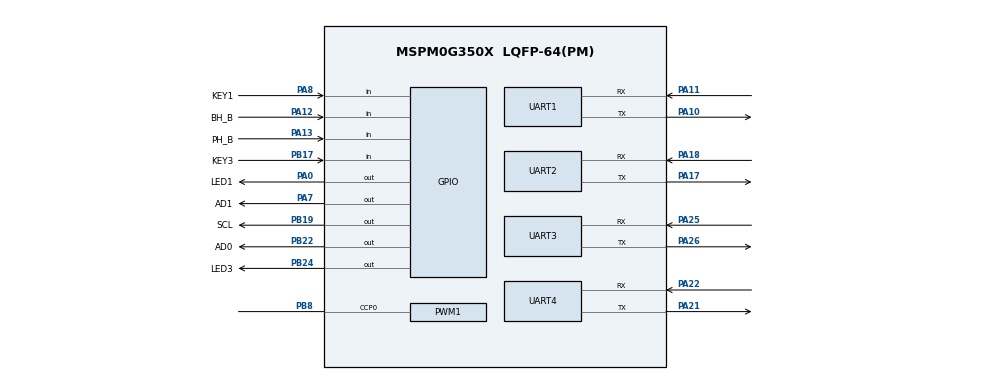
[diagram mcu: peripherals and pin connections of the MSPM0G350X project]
/**
 * @cliArgs --device "MSPM0G350X" --part "Default" --package "LQFP-64(PM)" --product "mspm0_sdk@2.09.00.00"
 * @versions {"tool":"1.26.0+4407"}
 */

/**
 * Import the modules used in this configuration.
 */
const ADC12   = scripting.addModule("/ti/driverlib/ADC12", {}, false);
const ADC121  = ADC12.addInstance();
const GPIO    = scripting.addModule("/ti/driverlib/GPIO", {}, false);
const GPIO1   = GPIO.addInstance();
const GPIO2   = GPIO.addInstance();
const GPIO3   = GPIO.addInstance();
const GPIO4   = GPIO.addInstance();
const GPIO5   = GPIO.addInstance();
const GPIO6   = GPIO.addInstance();
const GPIO7   = GPIO.addInstance();
const GPIO8   = GPIO.addInstance();
const PWM     = scripting.addModule("/ti/driverlib/PWM", {}, false);
const PWM1    = PWM.addInstance();
const PWM2    = PWM.addInstance();
const SYSCTL  = scripting.addModule("/ti/driverlib/SYSCTL");
const SYSTICK = scripting.addModule("/ti/driverlib/SYSTICK");
const TIMER   = scripting.addModule("/ti/driverlib/TIMER", {}, false);
const TIMER1  = TIMER.addInstance();
const UART    = scripting.addModule("/ti/driverlib/UART", {}, false);
const UART1   = UART.addInstance();
const UART2   = UART.addInstance();
const UART3   = UART.addInstance();
const UART4   = UART.addInstance();

/**
 * Write custom configuration values to the imported modules.
 */
ADC121.$name                             = "ADC12_sensor";
ADC121.sampleTime1                       = "0. ms";
ADC121.sampleTime0                       = "0.01 ms";
ADC121.peripheral.$assign                = "ADC0";
ADC121.peripheral.adcPin0.$assign        = "PA27";
ADC121.adcPin0Config.$name               = "ti_driverlib_gpio_GPIOPinGeneric0";
ADC121.adcPin0Config.hideOutputInversion = scripting.forceWrite(false);

const Board = scripting.addModule("/ti/driverlib/Board", {}, false);

GPIO1.$name                          = "GPIO_LED";
GPIO1.associatedPins.create(4);
GPIO1.associatedPins[0].$name        = "LED1";
GPIO1.associatedPins[0].assignedPort = "PORTA";
GPIO1.associatedPins[0].assignedPin  = "0";
GPIO1.associatedPins[0].pin.$assign  = "PA0";
GPIO1.associatedPins[1].assignedPort = "PORTA";
GPIO1.associatedPins[1].assignedPin  = "16";
GPIO1.associatedPins[1].$name        = "LED2";
GPIO1.associatedPins[2].$name        = "LED3";
GPIO1.associatedPins[2].assignedPort = "PORTB";
GPIO1.associatedPins[2].assignedPin  = "24";
GPIO1.associatedPins[2].pin.$assign  = "PB24";
GPIO1.associatedPins[3].$name        = "LED4";
GPIO1.associatedPins[3].assignedPort = "PORTA";
GPIO1.associatedPins[3].assignedPin  = "24";

GPIO2.$name                          = "GPIO_SENSOR";
GPIO2.associatedPins.create(3);
GPIO2.associatedPins[0].$name        = "AD0";
GPIO2.associatedPins[0].invert       = "ENABLE";
GPIO2.associatedPins[0].assignedPort = "PORTB";
GPIO2.associatedPins[0].assignedPin  = "22";
GPIO2.associatedPins[0].pin.$assign  = "PB22";
GPIO2.associatedPins[1].$name        = "AD1";
GPIO2.associatedPins[1].assignedPort = "PORTA";
GPIO2.associatedPins[1].assignedPin  = "7";
GPIO2.associatedPins[1].pin.$assign  = "PA7";
GPIO2.associatedPins[2].$name        = "AD2";
GPIO2.associatedPins[2].assignedPort = "PORTB";
GPIO2.associatedPins[2].assignedPin  = "14";

GPIO3.$name                          = "GPIO_Encoder";
GPIO3.associatedPins.create(4);
GPIO3.associatedPins[0].direction    = "INPUT";
GPIO3.associatedPins[0].assignedPort = "PORTB";
GPIO3.associatedPins[0].assignedPin  = "13";
GPIO3.associatedPins[0].interruptEn  = true;
GPIO3.associatedPins[0].polarity     = "RISE_FALL";
GPIO3.associatedPins[0].$name        = "PH_A";
GPIO3.associatedPins[1].$name        = "PH_B";
GPIO3.associatedPins[1].direction    = "INPUT";
GPIO3.associatedPins[1].interruptEn  = true;
GPIO3.associatedPins[1].polarity     = "RISE_FALL";
GPIO3.associatedPins[1].assignedPort = "PORTA";
GPIO3.associatedPins[1].assignedPin  = "13";
GPIO3.associatedPins[1].pin.$assign  = "PA13";
GPIO3.associatedPins[2].$name        = "BH_B";
GPIO3.associatedPins[2].assignedPort = "PORTA";
GPIO3.associatedPins[2].assignedPin  = "12";
GPIO3.associatedPins[2].direction    = "INPUT";
GPIO3.associatedPins[2].interruptEn  = true;
GPIO3.associatedPins[2].polarity     = "RISE_FALL";
GPIO3.associatedPins[2].pin.$assign  = "PA12";
GPIO3.associatedPins[3].direction    = "INPUT";
GPIO3.associatedPins[3].assignedPort = "PORTB";
GPIO3.associatedPins[3].assignedPin  = "23";
GPIO3.associatedPins[3].$name        = "BH_A";
GPIO3.associatedPins[3].interruptEn  = true;
GPIO3.associatedPins[3].polarity     = "RISE_FALL";

GPIO4.$name                          = "GPIO_MOTOR";
GPIO4.associatedPins.create(4);
GPIO4.associatedPins[0].$name        = "AIN1";
GPIO4.associatedPins[0].assignedPort = "PORTB";
GPIO4.associatedPins[0].assignedPin  = "27";
GPIO4.associatedPins[1].$name        = "AIN2";
GPIO4.associatedPins[1].assignedPort = "PORTB";
GPIO4.associatedPins[1].assignedPin  = "3";
GPIO4.associatedPins[2].$name        = "BIN1";
GPIO4.associatedPins[2].assignedPort = "PORTB";
GPIO4.associatedPins[2].assignedPin  = "15";
GPIO4.associatedPins[3].$name        = "BIN2";
GPIO4.associatedPins[3].assignedPort = "PORTB";
GPIO4.associatedPins[3].assignedPin  = "4";

GPIO5.$name                              = "GPIO_KEY";
GPIO5.associatedPins.create(4);
GPIO5.associatedPins[0].$name            = "KEY1";
GPIO5.associatedPins[0].direction        = "INPUT";
GPIO5.associatedPins[0].assignedPort     = "PORTA";
GPIO5.associatedPins[0].assignedPin      = "8";
GPIO5.associatedPins[0].internalResistor = "PULL_UP";
GPIO5.associatedPins[0].pin.$assign      = "PA8";
GPIO5.associatedPins[1].$name            = "KEY2";
GPIO5.associatedPins[1].direction        = "INPUT";
GPIO5.associatedPins[1].assignedPort     = "PORTA";
GPIO5.associatedPins[1].assignedPin      = "14";
GPIO5.associatedPins[1].internalResistor = "PULL_UP";
GPIO5.associatedPins[2].$name            = "KEY3";
GPIO5.associatedPins[2].direction        = "INPUT";
GPIO5.associatedPins[2].assignedPort     = "PORTB";
GPIO5.associatedPins[2].assignedPin      = "17";
GPIO5.associatedPins[2].internalResistor = "PULL_UP";
GPIO5.associatedPins[2].pin.$assign      = "PB17";
GPIO5.associatedPins[3].$name            = "KEY4";
GPIO5.associatedPins[3].direction        = "INPUT";
GPIO5.associatedPins[3].internalResistor = "PULL_UP";
GPIO5.associatedPins[3].assignedPort     = "PORTB";
GPIO5.associatedPins[3].assignedPin      = "18";

GPIO6.$name                          = "GPIO_OLED";
GPIO6.associatedPins.create(2);
GPIO6.associatedPins[0].$name        = "PIN_OLED_SDA";
GPIO6.associatedPins[0].assignedPort = "PORTB";
GPIO6.associatedPins[0].assignedPin  = "16";
GPIO6.associatedPins[1].$name        = "PIN_OLED_SCL";
GPIO6.associatedPins[1].assignedPort = "PORTA";
GPIO6.associatedPins[1].assignedPin  = "31";

GPIO7.$name                              = "GPIO_VOICE";
GPIO7.associatedPins.create(2);
GPIO7.associatedPins[0].$name            = "SCL";
GPIO7.associatedPins[0].assignedPort     = "PORTB";
GPIO7.associatedPins[0].assignedPin      = "19";
GPIO7.associatedPins[0].internalResistor = "PULL_UP";
GPIO7.associatedPins[0].initialValue     = "SET";
GPIO7.associatedPins[0].pin.$assign      = "PB19";
GPIO7.associatedPins[1].$name            = "SDA";
GPIO7.associatedPins[1].assignedPort     = "PORTB";
GPIO7.associatedPins[1].assignedPin      = "20";
GPIO7.associatedPins[1].initialValue     = "SET";
GPIO7.associatedPins[1].internalResistor = "PULL_UP";

GPIO8.$name                          = "GPIO_BUZZER";
GPIO8.associatedPins[0].$name        = "BEEP";
GPIO8.associatedPins[0].assignedPort = "PORTB";
GPIO8.associatedPins[0].assignedPin  = "21";

PWM1.dutyArgs                           = "[25,75,0,0]";
PWM1.ccIndex                            = [0];
PWM1.$name                              = "PWMB";
PWM1.timerStartTimer                    = true;
PWM1.PWM_CHANNEL_0.$name                = "ti_driverlib_pwm_PWMTimerCC0";
PWM1.PWM_CHANNEL_0.dutyCycle            = 0;
PWM1.PWM_CHANNEL_0.shadowUpdateMode     = "ZERO_EVT";
PWM1.ccp0PinConfig.$name                = "ti_driverlib_gpio_GPIOPinGeneric1";
PWM1.ccp0PinConfig.direction            = scripting.forceWrite("OUTPUT");
PWM1.ccp0PinConfig.hideOutputInversion  = scripting.forceWrite(false);
PWM1.ccp0PinConfig.onlyInternalResistor = scripting.forceWrite(false);
PWM1.ccp0PinConfig.passedPeripheralType = scripting.forceWrite("Digital");
PWM1.peripheral.$assign                 = "TIMA0";
PWM1.peripheral.ccp0Pin.$assign         = "PB8";

PWM2.$name                              = "PWMA";
PWM2.ccIndex                            = [1];
PWM2.timerStartTimer                    = true;
PWM2.ccp1PinConfig.direction            = scripting.forceWrite("OUTPUT");
PWM2.ccp1PinConfig.hideOutputInversion  = scripting.forceWrite(false);
PWM2.ccp1PinConfig.onlyInternalResistor = scripting.forceWrite(false);
PWM2.ccp1PinConfig.passedPeripheralType = scripting.forceWrite("Digital");
PWM2.ccp1PinConfig.$name                = "ti_driverlib_gpio_GPIOPinGeneric2";
PWM2.PWM_CHANNEL_1.$name                = "ti_driverlib_pwm_PWMTimerCC1";
PWM2.PWM_CHANNEL_1.shadowUpdateMode     = "ZERO_EVT";
PWM2.PWM_CHANNEL_1.ccValue              = 0;

SYSCTL.forceDefaultClkConfig = true;

SYSTICK.periodEnable      = true;
SYSTICK.period            = 32000;
SYSTICK.systickEnable     = true;
SYSTICK.interruptEnable   = true;
SYSTICK.interruptPriority = "3";

TIMER1.$name              = "TIMER_TICK";
TIMER1.timerMode          = "PERIODIC";
TIMER1.timerPeriod        = "20 ms";
TIMER1.interrupts         = ["ZERO"];
TIMER1.timerClkPrescale   = 256;
TIMER1.peripheral.$assign = "TIMG0";

UART1.$name                            = "UART_JY61P";
UART1.targetBaudRate                   = 115200;
UART1.enableFIFO                       = true;
UART1.rxFifoThreshold                  = "DL_UART_RX_FIFO_LEVEL_ONE_ENTRY";
UART1.enableDMARX                      = false;
UART1.enableDMATX                      = false;
UART1.enabledInterrupts                = ["RX"];
UART1.peripheral.$assign               = "UART0";
UART1.peripheral.rxPin.$assign         = "PA11";
UART1.peripheral.txPin.$assign         = "PA10";
UART1.txPinConfig.direction            = scripting.forceWrite("OUTPUT");
UART1.txPinConfig.hideOutputInversion  = scripting.forceWrite(false);
UART1.txPinConfig.onlyInternalResistor = scripting.forceWrite(false);
UART1.txPinConfig.passedPeripheralType = scripting.forceWrite("Digital");
UART1.txPinConfig.$name                = "ti_driverlib_gpio_GPIOPinGeneric3";
UART1.rxPinConfig.hideOutputInversion  = scripting.forceWrite(false);
UART1.rxPinConfig.onlyInternalResistor = scripting.forceWrite(false);
UART1.rxPinConfig.passedPeripheralType = scripting.forceWrite("Digital");
UART1.rxPinConfig.$name                = "ti_driverlib_gpio_GPIOPinGeneric4";

UART2.$name                            = "UART_VOFA";
UART2.targetBaudRate                   = 115200;
UART2.peripheral.$assign               = "UART1";
UART2.peripheral.rxPin.$assign         = "PA18";
UART2.peripheral.txPin.$assign         = "PA17";
UART2.txPinConfig.$name                = "ti_driverlib_gpio_GPIOPinGeneric7";
UART2.txPinConfig.direction            = scripting.forceWrite("OUTPUT");
UART2.txPinConfig.hideOutputInversion  = scripting.forceWrite(false);
UART2.txPinConfig.onlyInternalResistor = scripting.forceWrite(false);
UART2.txPinConfig.passedPeripheralType = scripting.forceWrite("Digital");
UART2.rxPinConfig.$name                = "ti_driverlib_gpio_GPIOPinGeneric8";
UART2.rxPinConfig.hideOutputInversion  = scripting.forceWrite(false);
UART2.rxPinConfig.onlyInternalResistor = scripting.forceWrite(false);
UART2.rxPinConfig.passedPeripheralType = scripting.forceWrite("Digital");

UART3.$name                            = "UART_K230";
UART3.targetBaudRate                   = 115200;
UART3.enabledInterrupts                = ["RX"];
UART3.interruptPriority                = "1";
UART3.peripheral.rxPin.$assign         = "PA25";
UART3.peripheral.txPin.$assign         = "PA26";
UART3.txPinConfig.$name                = "ti_driverlib_gpio_GPIOPinGeneric9";
UART3.txPinConfig.direction            = scripting.forceWrite("OUTPUT");
UART3.txPinConfig.hideOutputInversion  = scripting.forceWrite(false);
UART3.txPinConfig.onlyInternalResistor = scripting.forceWrite(false);
UART3.txPinConfig.passedPeripheralType = scripting.forceWrite("Digital");
UART3.rxPinConfig.$name                = "ti_driverlib_gpio_GPIOPinGeneric10";
UART3.rxPinConfig.hideOutputInversion  = scripting.forceWrite(false);
UART3.rxPinConfig.onlyInternalResistor = scripting.forceWrite(false);
UART3.rxPinConfig.passedPeripheralType = scripting.forceWrite("Digital");

UART4.$name                            = "UART_0";
UART4.peripheral.$assign               = "UART2";
UART4.peripheral.rxPin.$assign         = "PA22";
UART4.peripheral.txPin.$assign         = "PA21";
UART4.txPinConfig.$name                = "ti_driverlib_gpio_GPIOPinGeneric11";
UART4.txPinConfig.direction            = scripting.forceWrite("OUTPUT");
UART4.txPinConfig.hideOutputInversion  = scripting.forceWrite(false);
UART4.txPinConfig.onlyInternalResistor = scripting.forceWrite(false);
UART4.txPinConfig.passedPeripheralType = scripting.forceWrite("Digital");
UART4.rxPinConfig.$name                = "ti_driverlib_gpio_GPIOPinGeneric12";
UART4.rxPinConfig.hideOutputInversion  = scripting.forceWrite(false);
UART4.rxPinConfig.onlyInternalResistor = scripting.forceWrite(false);
UART4.rxPinConfig.passedPeripheralType = scripting.forceWrite("Digital");

/**
 * Pinmux solution for unlocked pins/peripherals. This ensures that minor changes to the automatic solver in a future
 * version of the tool will not impact the pinmux you originally saw.  These lines can be completely deleted in order to
 * re-solve from scratch.
 */
Board.peripheral.$suggestSolution            = "DEBUGSS";
Board.peripheral.swclkPin.$suggestSolution   = "PA20";
Board.peripheral.swdioPin.$suggestSolution   = "PA19";
GPIO1.associatedPins[1].pin.$suggestSolution = "PA16";
GPIO1.associatedPins[3].pin.$suggestSolution = "PA24";
GPIO2.associatedPins[2].pin.$suggestSolution = "PB14";
GPIO3.associatedPins[0].pin.$suggestSolution = "PB13";
GPIO3.associatedPins[3].pin.$suggestSolution = "PB23";
GPIO4.associatedPins[0].pin.$suggestSolution = "PB27";
GPIO4.associatedPins[1].pin.$suggestSolution = "PB3";
GPIO4.associatedPins[2].pin.$suggestSolution = "PB15";
GPIO4.associatedPins[3].pin.$suggestSolution = "PB4";
GPIO5.associatedPins[1].pin.$suggestSolution = "PA14";
GPIO5.associatedPins[3].pin.$suggestSolution = "PB18";
GPIO6.associatedPins[0].pin.$suggestSolution = "PB16";
GPIO6.associatedPins[1].pin.$suggestSolution = "PA31";
GPIO7.associatedPins[1].pin.$suggestSolution = "PB20";
GPIO8.associatedPins[0].pin.$suggestSolution = "PB21";
PWM2.peripheral.$suggestSolution             = "TIMA1";
PWM2.peripheral.ccp1Pin.$suggestSolution     = "PB1";
SYSCTL.peripheral.$suggestSolution           = "SYSCTL";
UART3.peripheral.$suggestSolution            = "UART3";
